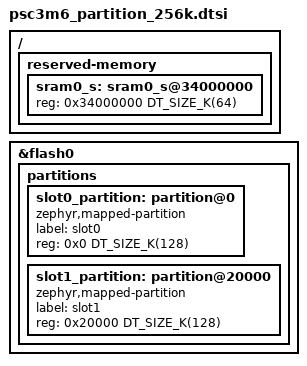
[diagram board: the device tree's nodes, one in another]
/*
 * SPDX-FileCopyrightText: Copyright (c) 2026 Infineon Technologies AG,
 * SPDX-FileCopyrightText: or an affiliate of Infineon Technologies AG. All rights reserved.
 *
 * SPDX-License-Identifier: Apache-2.0
 */

/*
 * Two 128 KB mcuboot slots, 256 KB total. Valid only for the 256 KB-flash,
 * 64 KB-RAM PSC3M6 MPNs (psc3m6fds2a*q1). The 512 KB MPNs (psc3m6ges3a*q1)
 * must use psc3m6_partition_512k.dtsi instead.
 */
/ {
	reserved-memory {
		#address-cells = <1>;
		#size-cells = <1>;
		ranges;

		sram0_s: sram0_s@34000000 {
			/* Secure image SRAM */
			reg = <0x34000000 DT_SIZE_K(64)>;
		};
	};
};

&flash0 {
	partitions {
		ranges;
		#address-cells = <1>;
		#size-cells = <1>;

		slot0_partition: partition@0 {
			compatible = "zephyr,mapped-partition";
			label = "slot0";
			reg = <0x0 DT_SIZE_K(128)>;
		};

		slot1_partition: partition@20000 {
			compatible = "zephyr,mapped-partition";
			label = "slot1";
			reg = <0x20000 DT_SIZE_K(128)>;
		};
	};
};
